# APM32F465 register map
File version: 1.0
CPU: CM4 r1p0, little endian, no MPU, no FPU, 3 interrupt priority bits
Registers are 32-bit, read-write, reset 0x0 unless marked. A register's access mark holds for its fields unless they carry their own. Offsets are from the block's base; [hi:lo] are bit positions; {n}, {i} and the like mark numbered series; 'fields as' and 'values as' point back to an identical list.

## RTC — Real-time clock
Base 0x40002800
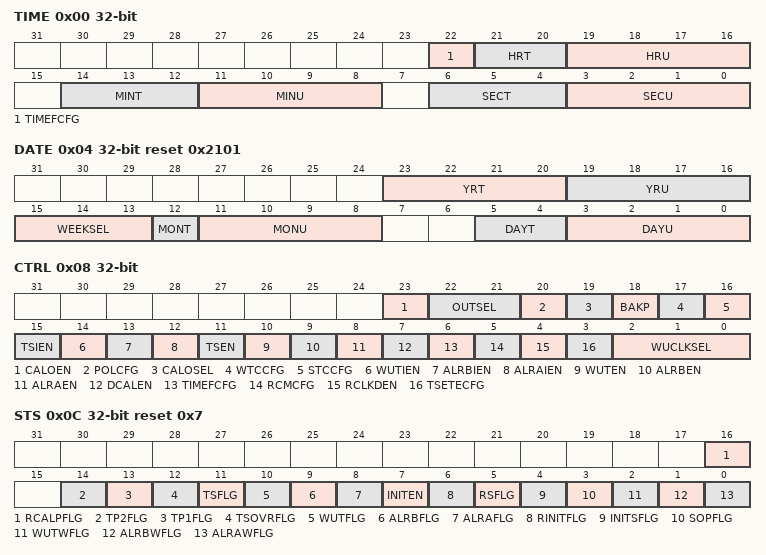
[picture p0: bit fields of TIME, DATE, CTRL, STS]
0x00 TIME
  [22] TIMEFCFG — AM/PM notation
  [21:20] HRT — Hour tens in BCD format
  [19:16] HRU — Hour units in BCD format
  [14:12] MINT — Minute tens in BCD format
  [11:8] MINU — Minute units in BCD format
  [6:4] SECT — Second tens in BCD format
  [3:0] SECU — Second units in BCD format
0x04 DATE reset 0x2101
  [23:20] YRT — Year tens in BCD format
  [19:16] YRU — Year units in BCD format
  [15:13] WEEKSEL — Week day units
  [12] MONT — Month tens in BCD format
  [11:8] MONU — Month units in BCD format
  [5:4] DAYT — Date tens in BCD format
  [3:0] DAYU — Date units in BCD format
0x08 CTRL — control register
  [23] CALOEN — Calibration output enable
  [22:21] OUTSEL — Output selection
  [20] POLCFG — Output polarity
  [19] CALOSEL — Calibration Output Value Select
  [18] BAKP — Backup
  [17] WTCCFG — Subtract 1 hour (winter time change)
  [16] STCCFG — Add 1 hour (summer time change)
  [15] TSIEN — Time-stamp interrupt enable
  [14] WUTIEN — Wakeup timer interrupt enable
  [13] ALRBIEN — Alarm B interrupt enable
  [12] ALRAIEN — Alarm A interrupt enable
  [11] TSEN — Time stamp enable
  [10] WUTEN — Wakeup timer enable
  [9] ALRBEN — Alarm B enable
  [8] ALRAEN — Alarm A enable
  [7] DCALEN — Coarse digital calibration enable
  [6] TIMEFCFG — Hour format
  [5] RCMCFG — Read Calendar Value Mode Configure
  [4] RCLKDEN — Reference clock detection enable (50 or 60 Hz)
  [3] TSETECFG — Time-stamp event active edge
  [2:0] WUCLKSEL — Wakeup clock selection
0x0C STS access per field reset 0x7 — initialization and status register
  [16] RCALPFLG ro — Recalibration pending Flag
  [14] TP2FLG rw — TAMPER2 detection flag
  [13] TP1FLG rw — Tamper detection flag
  [12] TSOVRFLG rw — Time-stamp overflow flag
  [11] TSFLG rw — Time-stamp flag
  [10] WUTFLG rw — Wakeup timer flag
  [9] ALRBFLG rw — Alarm B flag
  [8] ALRAFLG rw — Alarm A flag
  [7] INITEN rw — Initialization Mode Enable
  [6] RINITFLG ro — Register Initialization Occur Flag
  [5] RSFLG rw — Registers synchronization flag
  [4] INITSFLG ro — Initialization status flag
  [3] SOPFLG rw — Shift operation pending
  [2] WUTWFLG ro — Wakeup timer write flag
  [1] ALRBWFLG ro — Alarm B write flag
  [0] ALRAWFLG ro — Alarm A write flag
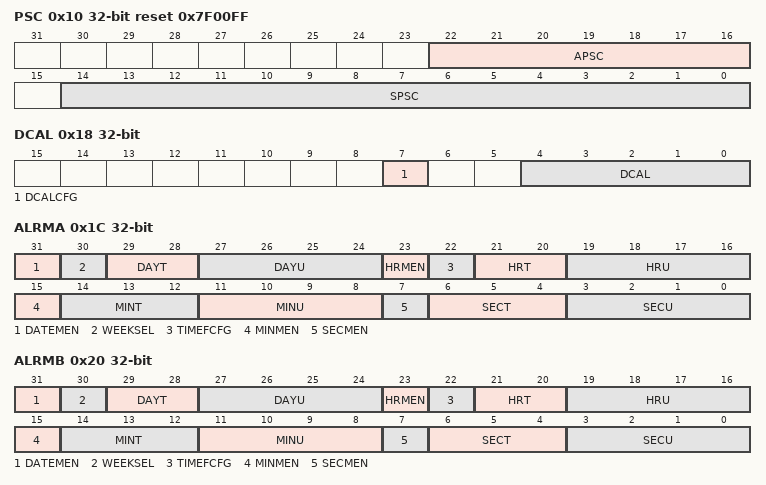
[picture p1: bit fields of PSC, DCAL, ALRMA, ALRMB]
0x10 PSC reset 0x7F00FF — prescaler register
  [22:16] APSC — Asynchronous prescaler factor
  [14:0] SPSC — Synchronous prescaler factor
0x14 AUTORLD reset 0xFFFF — wakeup timer register
  [15:0] WUAUTORE — Wakeup auto-reload value bits
0x18 DCAL — calibration register
  [7] DCALCFG — Digital calibration sign
  [4:0] DCAL — Digital calibration
0x1C ALRMA — alarm A register
  [31] DATEMEN — Alarm A date mask
  [30] WEEKSEL — Week day selection
  [29:28] DAYT — Date tens in BCD format
  [27:24] DAYU — Date units or day in BCD format
  [23] HRMEN — Alarm A hours mask
  [22] TIMEFCFG — AM/PM notation
  [21:20] HRT — Hour tens in BCD format
  [19:16] HRU — Hour units in BCD format
  [15] MINMEN — Alarm A minutes mask
  [14:12] MINT — Minute tens in BCD format
  [11:8] MINU — Minute units in BCD format
  [7] SECMEN — Alarm A seconds mask
  [6:4] SECT — Second tens in BCD format
  [3:0] SECU — Second units in BCD format
0x20 ALRMB — alarm B register
  fields as ALRMA
0x24 WRPROT wo — write protection register
  [7:0] KEY — Write protection key
0x28 SUBSEC ro — sub second register
  [15:0] SUBSEC — Sub second value
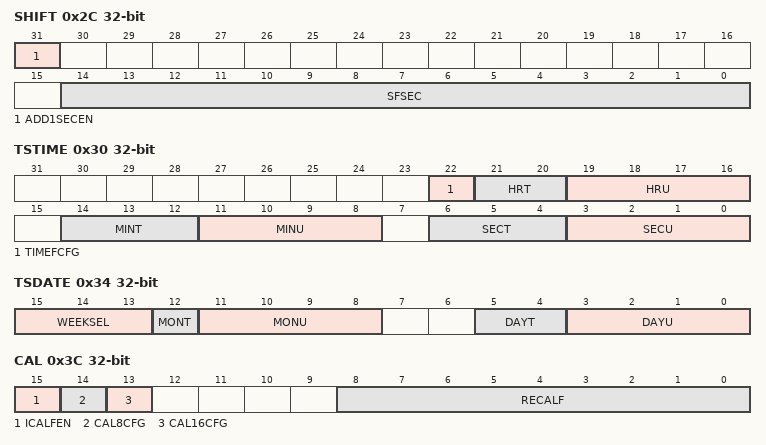
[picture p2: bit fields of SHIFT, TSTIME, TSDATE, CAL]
0x2C SHIFT wo — shift control register
  [31] ADD1SECEN — Add one second
  [14:0] SFSEC — Subtract a fraction of a second
0x30 TSTIME ro — time stamp time register
  [22] TIMEFCFG — Time Format Configure
  [21:20] HRT — Hour Ten's Place in BCD Format Setup
  [19:16] HRU — Hour Ones Unit in BCD Format Setup
  [14:12] MINT — Minute Ten's Place in BCD Format Setup
  [11:8] MINU — Minute Ones Unit in BCD Format Setup
  [6:4] SECT — Second Ten's Place in BCD Format Setup
  [3:0] SECU — Second Ones Unit in BCD Format Setup
0x34 TSDATE ro — time stamp date register
  [15:13] WEEKSEL — Week day units
  [12] MONT — Month tens in BCD format
  [11:8] MONU — Month units in BCD format
  [5:4] DAYT — Date tens in BCD format
  [3:0] DAYU — Date units in BCD format
0x38 TSSUBSEC ro — timestamp sub second register
  [15:0] SUBSEC — Sub Second Value Setup
0x3C CAL — calibration register
  [15] ICALFEN — Increase frequency of RTC by 488.5 ppm
  [14] CAL8CFG — Use an 8-second calibration cycle period
  [13] CAL16CFG — Use a 16-second calibration cycle period
  [8:0] RECALF — Calibration minus
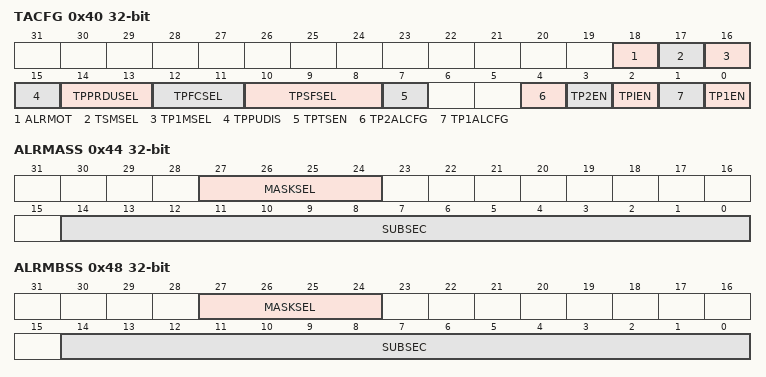
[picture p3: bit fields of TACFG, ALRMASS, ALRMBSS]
0x40 TACFG — tamper and alternate function configuration register
  [18] ALRMOT — AFO_ALARM output type
  [17] TSMSEL — TIMESTAMP mapping
  [16] TP1MSEL — TAMPER1 mapping
  [15] TPPUDIS — TAMPER pull-up disable
  [14:13] TPPRDUSEL — Tamper precharge duration
  [12:11] TPFCSEL — Tamper filter count
  [10:8] TPSFSEL — Tamper sampling frequency
  [7] TPTSEN — Activate timestamp on tamper detection event
  [4] TP2ALCFG — Active level for tamper 2
  [3] TP2EN — Tamper 2 detection enable
  [2] TPIEN — Tamper interrupt enable
  [1] TP1ALCFG — Active level for tamper 1
  [0] TP1EN — Tamper 1 detection enable
0x44 ALRMASS — alarm A sub second register
  [27:24] MASKSEL — Mask the most-significant bits starting at this bit
  [14:0] SUBSEC — Sub seconds value
0x48 ALRMBSS — alarm B sub second register
  fields as ALRMASS
{0x50+4i} BAKP{i} (i=0..19) — backup register
  [31:0] BAKP — Backup Value Setup
